# CMS32M6510 register map
Vendor: CMS; Series: CMS32M6510; File version: 1.2
CPU: CM0+ r0p1, little endian, no MPU, no FPU, VTOR, 2 interrupt priority bits
Registers are 32-bit, read-write, reset 0x0 unless marked. A register's access mark holds for its fields unless they carry their own. Offsets are from the block's base; [hi:lo] are bit positions; lines under a group give offsets from that group; {n}, {i} and the like mark numbered series.

## I2C0 — I2C0 Decription
Base 0x40064300
0x00 I2CCONSET — I2CCONSET Description
0x04 I2CCONCLR wo — I2CCONCLR Description
0x08 I2CSTAT ro reset 0xF8 — I2CSTAT Description
0x0C I2CDAT — I2CDAT Description
0x10 I2CCLK — I2CCLK Description
0x14 I2CADR0 — I2CADR0 Description
0x18 I2CADM0 reset 0xFE — I2CADM0 Description
0x1C I2CXADR0 — I2CXADR0 Description
0x20 I2CXADM0 reset 0x1FE — I2CXADM0 Description
0x24 I2CRST wo — I2CRST Description
{0x20+8i} I2CADR{i} (i=1..3) — I2CADR{i} Description
{0x24+8i} I2CADM{i} reset 0xFE (i=1..3) — I2CADM{i} Description

## SSP0 — SSP0 Decription
Base 0x40063000
0x00 SSPCON — SSPCON Description
0x04 SSPSTAT ro reset 0x3 — SSPSTAT Description
0x08 SSPDAT — SSPDAT Description
0x0C SSPCLK — SSPCLK Description
0x10 SSPIMSC — SSPIMSC Description
0x14 SSPRIS ro reset 0x8 — SSPRIS Description
0x18 SSPMIS ro — SSPMIS Description
0x1C SSPICLR wo — SSPICLR Description
0x28 SSPCSCR — SSPCSCR Description

## ADC — ADC Decription
Base 0x40068000
0x00 ADCCON — ADCCON Description
0x04 ADCCON2 — ADCCON2 Description
0x08 ADCHWTG — ADCHWTG Description
0x0C ADCPWMTGDLY — ADCPWMTGDLY Description
0x10 ADCSCAN — ADCSCAN Description
0x14 ADCCMP0 — ADCCMP0 Description
0x1C ADCIMSC — ADCIMSC Description
0x20 ADCRIS ro — ADCRIS Description
0x24 ADCMIS ro — ADCMIS Description
0x28 ADCICLR wo — ADCICLR Description
0x2C ADCLOCK — ADCLOCK Description
0x30 ADCCHEPWM — ADCCHEPWM Description
0x34 ADCCHPTG0 — ADCCHPTG0 Description
0x38 ADCCHPTG1 — ADCCHPTG1 Description
0x48 ADCTEST — ADCCHPTG1 Description
{0x80+4i} ADCDATA{i} ro (i=0..18) — ADCDATA{i} Description
{0x80+4i} ADCDATA{i} ro (i=20..23) — ADCDATA{i} Description

## ADCLDO
Base 0x40068340
0x00 CON0 — CON0 Description
0x0C LOCK — LOCK Description

## DIVSQRT
Base 0x40064380
0x00 CON — CON0 Description
0x04 ALUA — ALUA Description
0x08 ALUB — ALUB Description
0x0C RES0 — RES0 Description
0x10 RES1 — RES1 Description

## DAC
Base 0x40068360
0x00 CON0 — CON Description
0x04 LOCK — LOCK Description

## PGA0
Base 0x40068300
0x00 PGA0CON0 — CON0 Description
0x04 PGA0CON1 — CON1 Description
0x08 PGA0LOCK — LOCK Description

## PGA12
Base 0x40068320
0x00 PGA1CON0 — PGA1CON0 Description
0x04 PGA2CON0 — PGA2CON0 Description
0x08 PGA12CON — PGA12CON Description
0x0C PGA12LOCK — LOCK Description

## ACMP — ACMP Decription
Base 0x40068200
0x00 C0CON0 — C0CON0 Description
0x04 C0CON1 reset 0x10 — C0CON1 Description
0x08 C1CON0 — C1CON0 Description
0x0C C1CON1 reset 0x10 — C1CON1 Description
0x10 CEVCON — CEVCON Description
0x14 IMSC — IMSC Description
0x18 RIS ro — RIS Description
0x1C MIS ro — MIS Description
0x20 ICLR wo — ICLR Description
0x24 LOCK — LOCK Description

## INT — Interrupt Controller
Base 0x40006000
{0x0+4i} IF[{i}] (i=0..31) group — Interrupt flag register
  0x00 IFL 8-bit (reset mask 0x1) — Interrupt flag register
{0x100+4i} MK[{i}] (i=0..31) group — Interrupt mask register
  0x00 MKL 8-bit reset 0xFFFFFFFF (reset mask 0x1) — Interrupt mask register

## INTM — Pin input edge detection
Base 0x40045B38
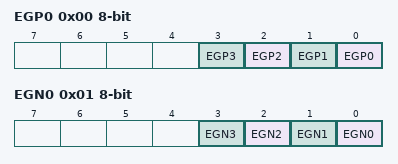
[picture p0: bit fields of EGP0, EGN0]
0x00 EGP0 8-bit — External interrupt rising edge enable register
  [n] EGP{n} (n=0..3)
0x01 EGN0 8-bit — External interrupt falling edge enable register
  [n] EGN{n} (n=0..3)

## MISC — Miscellaneous function
Base 0x40040470
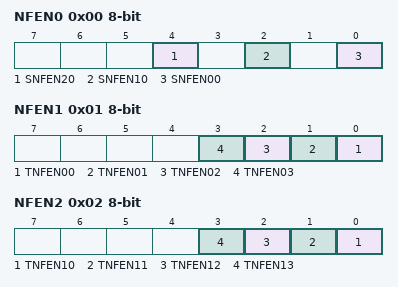
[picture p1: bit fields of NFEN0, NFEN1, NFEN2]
0x00 NFEN0 8-bit — Noise filter enable register 0
  [4] SNFEN20 — Enable noise filter of RxD2
  [2] SNFEN10 — Enable noise filter of RxD1
  [0] SNFEN00 — Enable noise filter of RxD0
0x01 NFEN1 8-bit — Noise filter enable register 1
  [n] TNFEN{n:02} (n=0..3) — Enable noise filter of TI{n:02}
0x02 NFEN2 8-bit — Noise filter enable register 2
  [n-10] TNFEN{n} (n=10..13) — Enable noise filter of TI{n}
0x03 ISC 8-bit — Input switch control register
  [7] SSIE00 — The slave select input (SS00) of SPI00 is valid
    0=INVALID (The slave select input (SS00) pin is invalid); 1=VALID (The slave select input (SS00) pin is valid)
0x04 TIOS0 8-bit (reset mask 0x83) — Timer I/O select register 0
0x05 TIOS1 8-bit (reset mask 0x1) — Timer I/O select register 1
0x0C RTCCL 8-bit (reset mask 0xE3) — Real-time clock select register

## FMC — Flash Memory Controller
Base 0x40020000
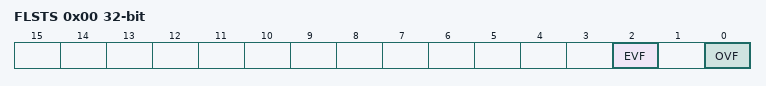
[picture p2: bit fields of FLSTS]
0x00 FLSTS — Flash status register
  [2] EVF — Flash hardware verification error flag
  [0] OVF — Flash erase or write operaiton finish
0x04 FLOPMD1 (reset mask 0xFF) — Flash operation mode register 1
0x08 FLOPMD2 (reset mask 0xFF) — Flash operation mode register 2
0x0C FLERMD (reset mask 0x18) — Flash erase mode register
0x10 FLCERCNT (reset mask 0x800001FF) — Flash chip erase control register
0x14 FLSERCNT (reset mask 0x800001FF) — Flash sector erase control register
0x18 FLNVSCNT (reset mask 0x800001FF) — Flash address setup time (Tnvs) control register
0x1C FLPROCNT (reset mask 0x81FF81FF) — Flash program control register
0x20 FLPROT (reset mask 0xFF) — Flash protect control register
0x38 FLPRVCNT (reset mask 0x800001FF) — Flash program recovery time (Trcv) control register
0x3C FLERVCNT (reset mask 0x803FF81FF) — Flash erase recovery time (Trcv) control register

## SAF — Flash memory CRC operation function (High-Speed CRC)
Base 0x40020100
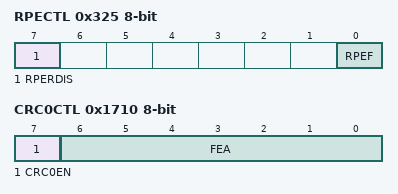
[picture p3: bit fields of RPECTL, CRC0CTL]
0x325 RPECTL 8-bit — RAM parity error control register
  [7] RPERDIS — Disable RAM parity error reset
    0=Enable parity error reset; 1=Disable parity error reset
  [0] RPEF — Parity error status flag
    0=NoError (No parity error has occurred); 1=Error (Parity error has occurred)
0x1710 CRC0CTL 8-bit — Flash memory CRC control register
  [7] CRC0EN — Control of high-speed CRC operation
  [6:0] FEA — High-speed CRC operation range
0x1712 PGCRCL 16-bit — Flash memory CRC operation result register
0x20378 SFRGD 16-bit (reset mask 0xF) — SFR guard control register
0x231FA CRCD 16-bit (reset mask 0xFF) — CRC data register
0x232AC CRCIN 8-bit — CRC input register

## CRC — General Purpose CRC
Base 0x400432F0
0x0A CRCD 16-bit (reset mask 0xFF) — CRC data register
0xBC CRCIN 8-bit — CRC input register

## DBG — DBG Controller
Base 0x4001B000
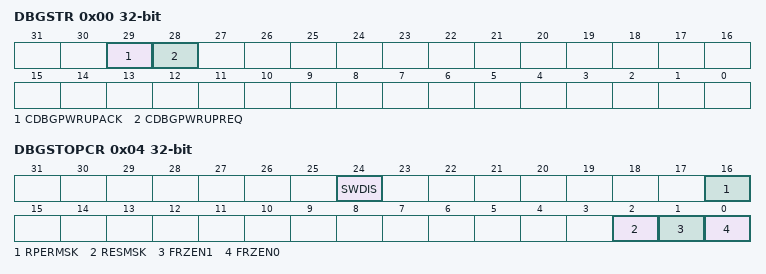
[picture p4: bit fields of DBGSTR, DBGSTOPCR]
0x00 DBGSTR ro — Debug status register
  [29] CDBGPWRUPACK — DBG Power Up Acknowledgement
  [28] CDBGPWRUPREQ — DBG Power Up Request
0x04 DBGSTOPCR — Debug Stop Control register
  [24] SWDIS — SWD Disable
  [16] RPERMSK — Mask RAM parity error in debug mode
  [2] RESMSK — Mask internal reset in debug mode
  [1] FRZEN1 — Stop Communation family macros when cpu halted
  [0] FRZEN0 — Stop Timer family macros when cpu halted

## BGR — Temperature Sensor calibration data
Base 0x00500660
0x00 VBG85 16-bit ro — The A/D conversion value of VBGR at 85 degrees and 3.0V reference voltage
0x04 VBG25 16-bit ro — The A/D conversion value of VBGR at 25 degrees and 3.0V reference voltage

## TSN — Temperature Sensor calibration data
Base 0x00500668
0x00 TSN85 16-bit ro — The A/D conversion value of Temperature Sensor at 85 degrees and 3.0V reference voltage
0x04 TSN25 16-bit ro — The A/D conversion value of Temperature Sensor at 25 degrees and 3.0V reference voltage

## UID — 128-bit Unique ID
Base 0x00500894
{0x0+4i} UID{i} (i=0..3) ro — UID word {i}
